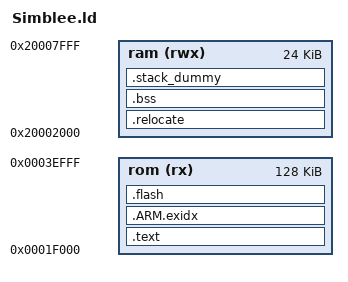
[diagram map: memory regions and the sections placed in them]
/*
 * Copyright (c) 2015 RF Digital Corp. All Rights Reserved.
 *
 * The source code contained in this file and all intellectual property embodied in
 * or covering the source code is the property of RF Digital Corp. or its licensors.
 * Your right to use this source code and intellectual property is non-transferable,
 * non-sub licensable, revocable, and subject to terms and conditions of the
 * SIMBLEE SOFTWARE LICENSE AGREEMENT.
 * http://www.simblee.com/licenses/SimbleeSoftwareLicenseAgreement.txt
 *
 * THE SOURCE CODE IS PROVIDED "AS IS" WITHOUT WARRANTY OF ANY KIND.
 *
 * This heading must NOT be removed from this file.
 */

OUTPUT_FORMAT("elf32-littlearm", "elf32-littlearm", "elf32-littlearm")
OUTPUT_ARCH(arm)
SEARCH_DIR(.)

/* Memory Spaces Definitions */
MEMORY
{
  rom (rx) : ORIGIN = 0x1F000, LENGTH = 128K
  ram (rwx) : ORIGIN = 0x20002000, LENGTH = 24K
}

/* Section Definitions */
SECTIONS
{
    .text :
    {
        . = ALIGN(4);
        _sfixed = .;
        KEEP(*(.vectors .vectors.*))
        *(.text .text.* .gnu.linkonce.t.*)
        *(.glue_7t) *(.glue_7)
        *(.rodata .rodata* .gnu.linkonce.r.*)
        *(.ARM.extab* .gnu.linkonce.armextab.*)
        KEEP(*(.keeptext .keeptext.*))

        /* Support C constructors, and C destructors in both user code
           and the C library. This also provides support for C++ code. */
        . = ALIGN(4);
        KEEP(*(.init))
        . = ALIGN(4);
        __preinit_array_start = .;
        KEEP (*(.preinit_array))
        __preinit_array_end = .;

        . = ALIGN(4);
        __init_array_start = .;
        KEEP (*(SORT(.init_array.*)))
        KEEP (*(.init_array))
        __init_array_end = .;

        . = ALIGN(0x4);
        KEEP (*crtbegin.o(.ctors))
        KEEP (*(EXCLUDE_FILE (*crtend.o) .ctors))
        KEEP (*(SORT(.ctors.*)))
        KEEP (*crtend.o(.ctors))

        . = ALIGN(4);
        KEEP(*(.fini))

        . = ALIGN(4);
        __fini_array_start = .;
        KEEP (*(.fini_array))
        KEEP (*(SORT(.fini_array.*)))
        __fini_array_end = .;

        KEEP (*crtbegin.o(.dtors))
        KEEP (*(EXCLUDE_FILE (*crtend.o) .dtors))
        KEEP (*(SORT(.dtors.*)))
        KEEP (*crtend.o(.dtors))

        . = ALIGN(4);
        _efixed = .;            /* End of text section */
    } > rom

    /* .ARM.exidx is sorted, so has to go in its own output section.  */
    PROVIDE_HIDDEN (__exidx_start = .);
    .ARM.exidx :
    {
      *(.ARM.exidx* .gnu.linkonce.armexidx.*)
    } > rom
    PROVIDE_HIDDEN (__exidx_end = .);

    . = ALIGN(4);
    _etext = .;
    
    .relocate : AT (_etext)
    {
        . = ALIGN(4);
        _srelocate = .;
        *(.ramfunc .ramfunc.*);
        *(.data .data.*);
        KEEP(*(.keepdata .keepdata.*))
        . = ALIGN(4);
        _erelocate = .;
    } > ram

    /* .bss section which is used for uninitialized data */
    .bss ALIGN(4) (NOLOAD) :
    {
        . = ALIGN(4);
        _sbss = . ;
        _szero = .;
        *(.bss .bss.*)
        KEEP(*(.keepbss .keepbss.*))
        *(COMMON)
        . = ALIGN(4);
        _ebss = . ;
        _ezero = .;
    } > ram

    . = ALIGN(4);
    _end = . ;

    /* .stack_dummy section doesn't contains any symbols. It is only
       used for linker to calculate size of stack sections, and assign
       values to stack symbols later */
    .stack_dummy :
    {
        *(.stack*)
    } > ram

    /* Set stack top to end of ram, and stack limit move down by
     * size of stack_dummy section */
    __StackTop = ORIGIN(ram) + LENGTH(ram);
    __StackLimit = __StackTop - SIZEOF(.stack_dummy);
    PROVIDE(_sstack = __StackLimit);
    PROVIDE(_estack = __StackTop);

    /* optional flash section located on the next flash page after the end of text relocation section 
       (should assist in the creation of initialized modifiable flash pages) */
    
    _etextrelocate = _etext + SIZEOF(.relocate);
    . = _etextrelocate;
    
    .flash ALIGN(1024) :
    {
    	*(.flash)
    } >rom
    
    _sflash = ADDR(.flash);
    _eflash = _sflash + SIZEOF(.flash);
}
